# TC37XPD register map
Vendor: Infineon; Series: ATVMC; File version: 100
CPU: other r0p0, little endian, MPU, FPU, vendor SysTick, 4 interrupt priority bits
Registers are 32-bit, read-write, reset 0x0 unless marked. A register's access mark holds for its fields unless they carry their own. Offsets are from the block's base; [hi:lo] are bit positions; lines under a group give offsets from that group; {n}, {i} and the like mark numbered series; 'fields as' and 'values as' point back to an identical list.

## SRC
Base 0xF0038000
0x00 CPU group
  {0x0+4j} CPU[{j}] (j=0..2) group
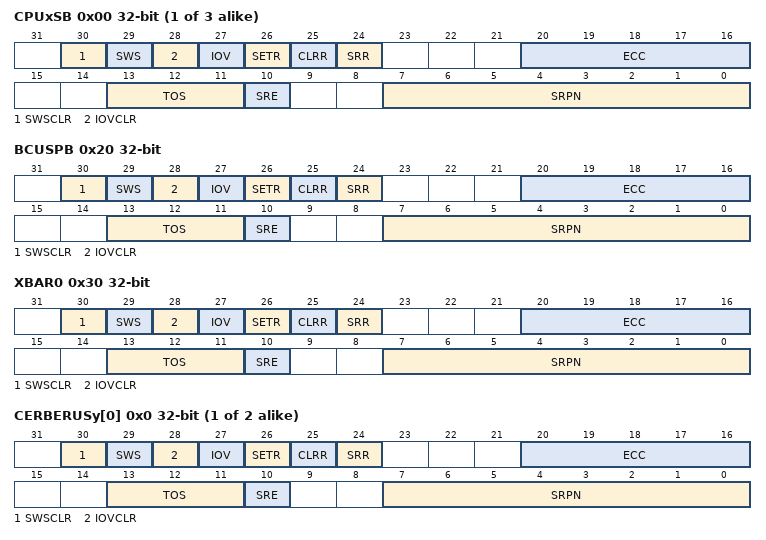
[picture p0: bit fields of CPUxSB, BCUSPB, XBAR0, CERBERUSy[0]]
    0x00 CPUxSB access per field — CPU0 Software Breakpoint Service Request resetvalue={Debug Reset:0x0}
      [30] SWSCLR wo — SW Sticky Clear Bit. SWSCLR is required to reset SWS SWS .
      [29] SWS ro — SW Sticky Bit. The Software Sticky Bit is set when the SRR SRR bit has been set via the SETR SETR bit. This bit can be cleared by writing with 1 to SWSCLR SWSCLR . Writing to SWS has no effect.
      [28] IOVCLR wo — Interrupt Trigger Overflow Clear Bit. IOVCLR is required to reset IOV IOV .
      [27] IOV ro — Interrupt Trigger Overflow Bit. The IOV bit is set by HW if a new service request was triggered via interrupt trigger or SETR SETR bit while the SRN has still an pending service request.
      [26] SETR wo — Request Set Bit. The SETR bit is required to set SRR SRR .
      [25] CLRR wo — Request Clear Bit. The CLRR bit is required to reset SRR SRR .
      [24] SRR ro — Service Request Flag. The SRR bit shows the status of the Service Request.
      [20:16] ECC rw — Error Correction Code. The ECC bit field will be updated by the SRN under the following conditions Write or Read Modify Write to SRC 31 0 Write to SRC 15 0 16 bit write Write to SRC 15 8 or write to SRC 7 0 byte write For more details pls. see CROSSREFERENCE . In the current implementation the ECC code is only used for error detection. Detected errors are reported to the SMU but not corrected.
      [13:11] TOS rw — Type of Service Control. The TOS bit field configuration maps a Service Request to an Interrupt Service Provider In products where DMA or CPUx is not implemented the related TOS encoding will not be used and treated as RESERVED. In products with less than 4 ISPs the effective size of the TOS bit field might be reduced to 1 or 2 bit.
      [10] SRE rw — Service Request Enable
      [7:0] SRPN rw — Service Request Priority Number. The SRPN bit field defines the priority of a service request with respect to service requests with to the same service provider same SRC.TOS configuration 00 gt Service request is on lowest priority ... FF gt Service request is on highest priority For a CPU 01 is the lowest priority as 00 is never serviced. For a DMA 00 triggers channel 0. For DMA SRPN must not be greater than the highest implemented DMA channel number.
0x20 BCUSPB access per field — SBCU Service Request SPB Bus Control Unit resetvalue={Debug Reset:0x0}
  fields as CPU.CPU[0].CPUxSB
0x30 XBAR0 access per field — SRI Domain 0 Service Request resetvalue={Debug Reset:0x0}
  fields as CPU.CPU[0].CPUxSB
0x40 CERBERUS group
  0x00 CERBERUS group
    {0x0+4k} CERBERUSy[{k}] (k=0..1) access per field — Cerberus Service Request 0 resetvalue={Debug Reset:0x0}
      fields as CPU.CPU[0].CPUxSB
0x50 ASCLIN group
  {0x0+0xC*j} ASCLIN[{j}] (j=0..11) group
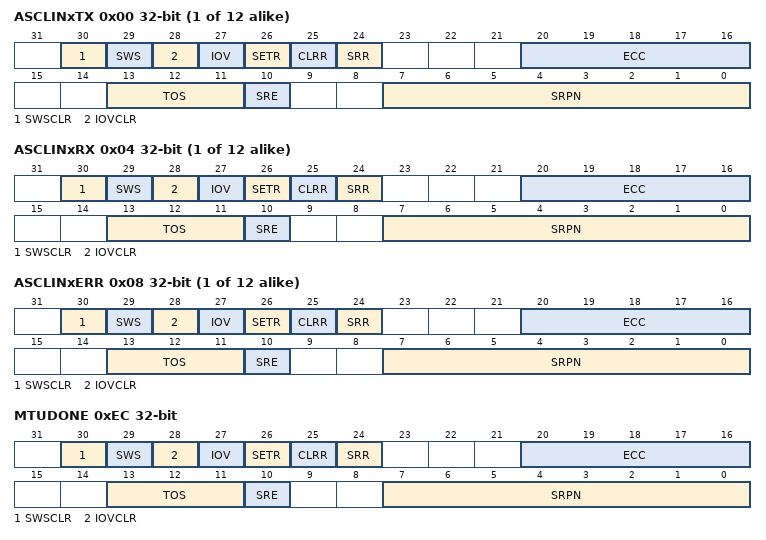
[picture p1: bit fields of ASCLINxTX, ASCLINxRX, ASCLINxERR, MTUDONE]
    0x00 ASCLINxTX access per field — ASCLIN0 Transmit Service Request resetvalue={Application Reset:0x0}
      fields as CPU.CPU[0].CPUxSB
    0x04 ASCLINxRX access per field — ASCLIN0 Receive Service Request resetvalue={Application Reset:0x0}
      fields as CPU.CPU[0].CPUxSB
    0x08 ASCLINxERR access per field — ASCLIN0 Error Service Request resetvalue={Application Reset:0x0}
      fields as CPU.CPU[0].CPUxSB
0xEC MTUDONE access per field — MTU Done Service Request resetvalue={Application Reset:0x0}
  fields as CPU.CPU[0].CPUxSB
0xF0 QSPI group
  {0x0+0x14*j} QSPI[{j}] (j=0..4) group
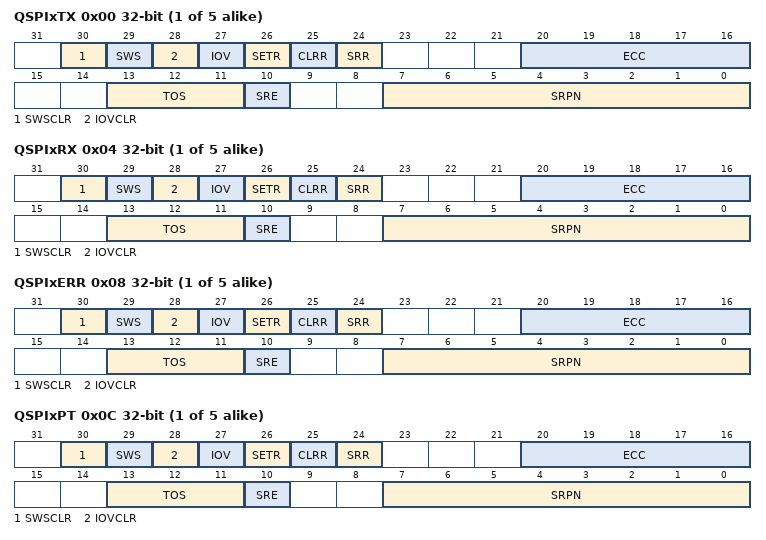
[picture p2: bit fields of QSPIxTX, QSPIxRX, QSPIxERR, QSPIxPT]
    0x00 QSPIxTX access per field — QSPI0 Transmit Service Request resetvalue={Application Reset:0x0}
      fields as CPU.CPU[0].CPUxSB
    0x04 QSPIxRX access per field — QSPI0 Receive Service Request resetvalue={Application Reset:0x0}
      fields as CPU.CPU[0].CPUxSB
    0x08 QSPIxERR access per field — QSPI0 Error Service Request resetvalue={Application Reset:0x0}
      fields as CPU.CPU[0].CPUxSB
    0x0C QSPIxPT access per field — QSPI0 Phase Transition Service Request resetvalue={Application Reset:0x0}
      fields as CPU.CPU[0].CPUxSB
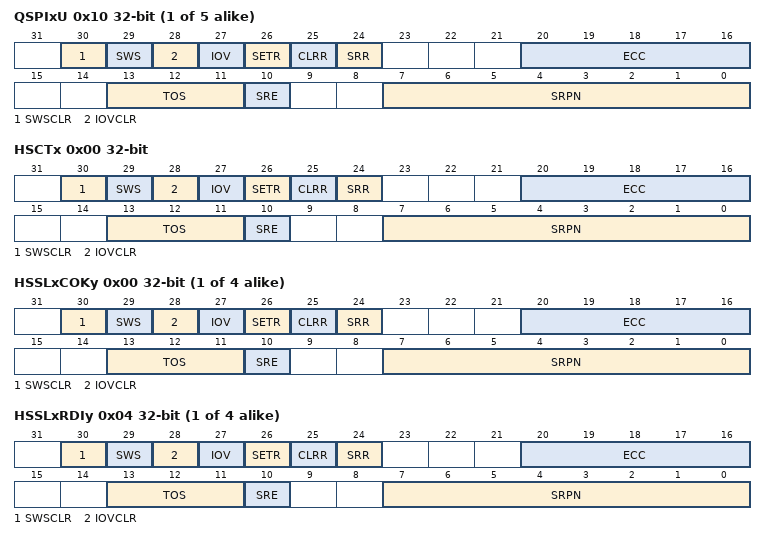
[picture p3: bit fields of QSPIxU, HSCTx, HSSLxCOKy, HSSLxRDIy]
    0x10 QSPIxU access per field — QSPI0 User Defined Service Request resetvalue={Application Reset:0x0}
      fields as CPU.CPU[0].CPUxSB
0x180 HSCT group
  {0x0+4j} HSCT[{j}] (j=0..0) group
    0x00 HSCTx access per field — HSCT0 Service Request resetvalue={Application Reset:0x0}
      fields as CPU.CPU[0].CPUxSB
0x190 HSSL group
  {0x0+0x44*j} HSSL[{j}] (j=0..0) group
    {0x0+0x10*k} CH[{k}] (k=0..3) group
      0x00 HSSLxCOKy access per field — HSSL0 Channel 0 OK Service Request resetvalue={Application Reset:0x0}
        fields as CPU.CPU[0].CPUxSB
      0x04 HSSLxRDIy access per field — HSSL0 Channel 0 Read Data Service Request resetvalue={Application Reset:0x0}
        fields as CPU.CPU[0].CPUxSB
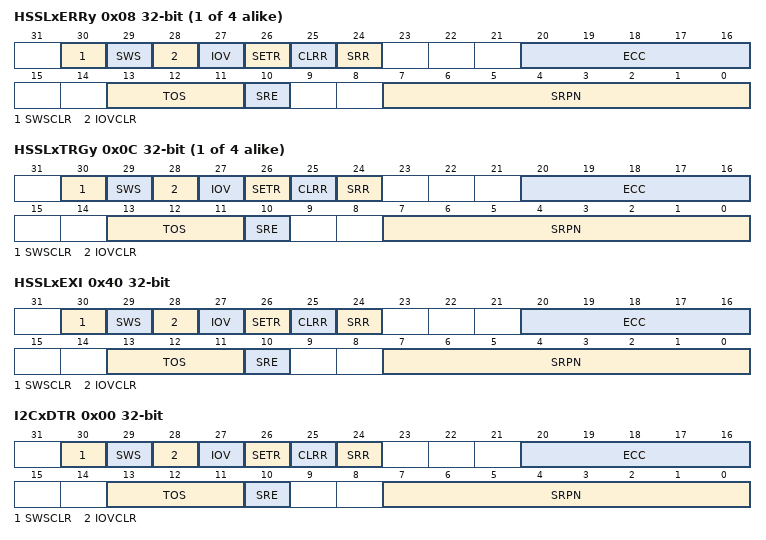
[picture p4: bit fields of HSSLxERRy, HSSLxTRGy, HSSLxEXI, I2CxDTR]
      0x08 HSSLxERRy access per field — HSSL0 Channel 0 Error Service Request resetvalue={Application Reset:0x0}
        fields as CPU.CPU[0].CPUxSB
      0x0C HSSLxTRGy access per field — HSSL0 Channel 0 Trigger Interrupt Service Request resetvalue={Application Reset:0x0}
        fields as CPU.CPU[0].CPUxSB
    0x40 HSSLxEXI access per field — HSSL0 Exception Service Request resetvalue={Application Reset:0x0}
      fields as CPU.CPU[0].CPUxSB
0x220 I2C group
  {0x0+0x10*j} I2C[{j}] (j=0..0) group
    0x00 I2CxDTR access per field — I2C0 Data Transfer Request resetvalue={Application Reset:0x0}
      fields as CPU.CPU[0].CPUxSB
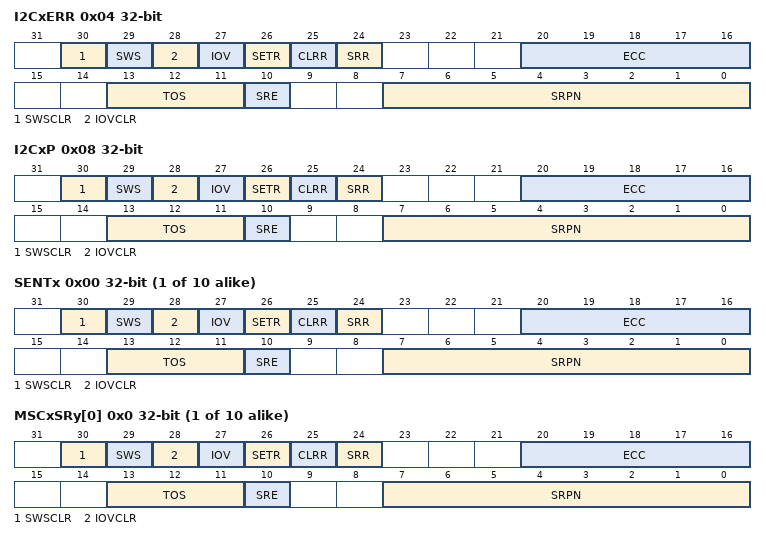
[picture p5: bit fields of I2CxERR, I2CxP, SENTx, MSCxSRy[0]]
    0x04 I2CxERR access per field — I2C0 Error Service Request resetvalue={Application Reset:0x0}
      fields as CPU.CPU[0].CPUxSB
    0x08 I2CxP access per field — I2C0 Protocol Service Request resetvalue={Application Reset:0x0}
      fields as CPU.CPU[0].CPUxSB
0x240 SENT group
  {0x0+4j} SENT[{j}] (j=0..9) group
    0x00 SENTx access per field — SENT TRIG0 Service Request resetvalue={Application Reset:0x0}
      fields as CPU.CPU[0].CPUxSB
0x270 MSC group
  {0x0+4j} MSC[{j}] (j=0..1) group
    {0x0+4k} MSCxSRy[{k}] (k=0..4) access per field — MSC0 Service Request 0 resetvalue={Application Reset:0x0}
      fields as CPU.CPU[0].CPUxSB
0x2C0 CCU6 group
  {0x0+4j} CCU[{j}] (j=0..1) group
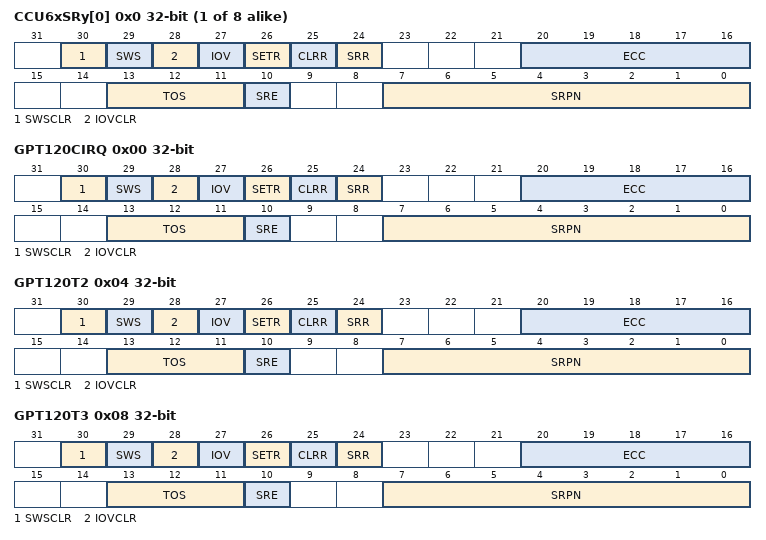
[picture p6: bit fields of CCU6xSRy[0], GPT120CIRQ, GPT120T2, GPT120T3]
    {0x0+4k} CCU6xSRy[{k}] (k=0..3) access per field — CCU0 Service Request 0 resetvalue={Application Reset:0x0}
      fields as CPU.CPU[0].CPUxSB
0x2E0 GPT12 group
  {0x0+0x18*j} GPT12[{j}] (j=0..0) group
    0x00 GPT120CIRQ access per field — GPT120 CAPREL Service Request resetvalue={Application Reset:0x0}
      fields as CPU.CPU[0].CPUxSB
    0x04 GPT120T2 access per field — GPT120 Timer 2 Service Request resetvalue={Application Reset:0x0}
      fields as CPU.CPU[0].CPUxSB
    0x08 GPT120T3 access per field — GPT120 Timer 3 Service Request resetvalue={Application Reset:0x0}
      fields as CPU.CPU[0].CPUxSB
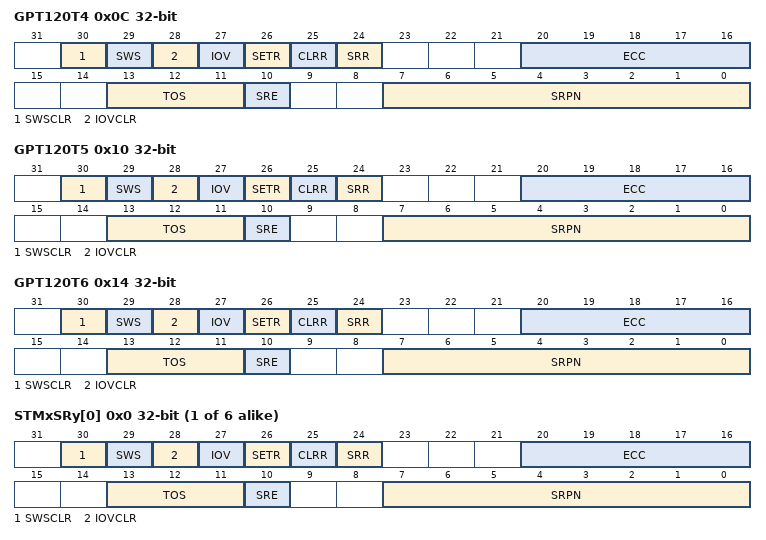
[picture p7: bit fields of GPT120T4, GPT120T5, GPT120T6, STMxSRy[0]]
    0x0C GPT120T4 access per field — GPT120 Timer 4 Service Request resetvalue={Application Reset:0x0}
      fields as CPU.CPU[0].CPUxSB
    0x10 GPT120T5 access per field — GPT120 Timer 5 Service Request resetvalue={Application Reset:0x0}
      fields as CPU.CPU[0].CPUxSB
    0x14 GPT120T6 access per field — GPT120 Timer 6 Service Request resetvalue={Application Reset:0x0}
      fields as CPU.CPU[0].CPUxSB
0x300 STM group
  {0x0+4j} STM[{j}] (j=0..2) group
    {0x0+4k} STMxSRy[{k}] (k=0..1) access per field — System Timer 0 Service Request 0 resetvalue={Application Reset:0x0}
      fields as CPU.CPU[0].CPUxSB
0x330 FCE group
  0x00 FCE0 group
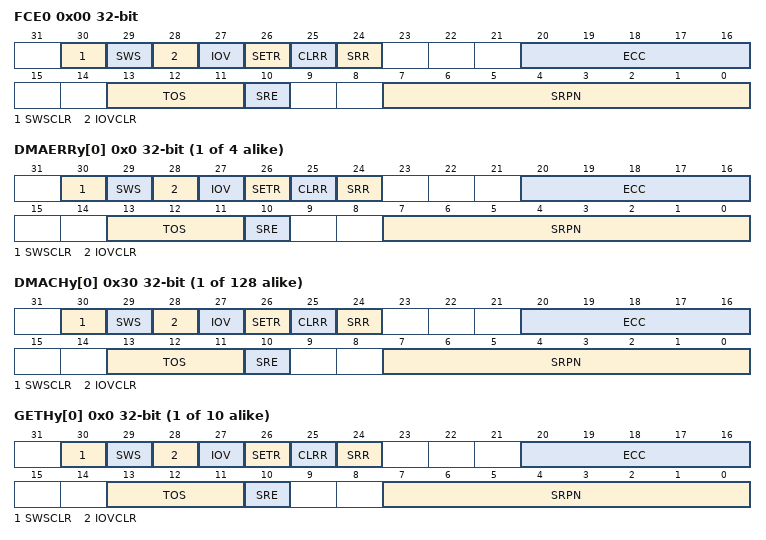
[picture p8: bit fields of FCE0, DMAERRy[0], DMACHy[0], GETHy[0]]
    0x00 FCE0 access per field — FCE0 Error Service Request resetvalue={Application Reset:0x0}
      fields as CPU.CPU[0].CPUxSB
0x340 DMA group
  {0x0+0x34*j} DMA[{j}] (j=0..0) group
    {0x0+4k} DMAERRy[{k}] (k=0..3) access per field — DMA Error Service Request 0 resetvalue={Application Reset:0x0}
      fields as CPU.CPU[0].CPUxSB
    {0x30+4k} DMACHy[{k}] (k=0..127) access per field — DMA Channel 0 Service Request resetvalue={Application Reset:0x0}
      fields as CPU.CPU[0].CPUxSB
0x580 GETH group
  {0x0+4j} GETH[{j}] (j=0..0) group
    {0x0+4k} GETHy[{k}] (k=0..9) access per field — GETH Service Request 0 resetvalue={Application Reset:0x0}
      fields as CPU.CPU[0].CPUxSB
0x5B0 CAN group
  {0x0+4j} CAN[{j}] (j=0..1) group
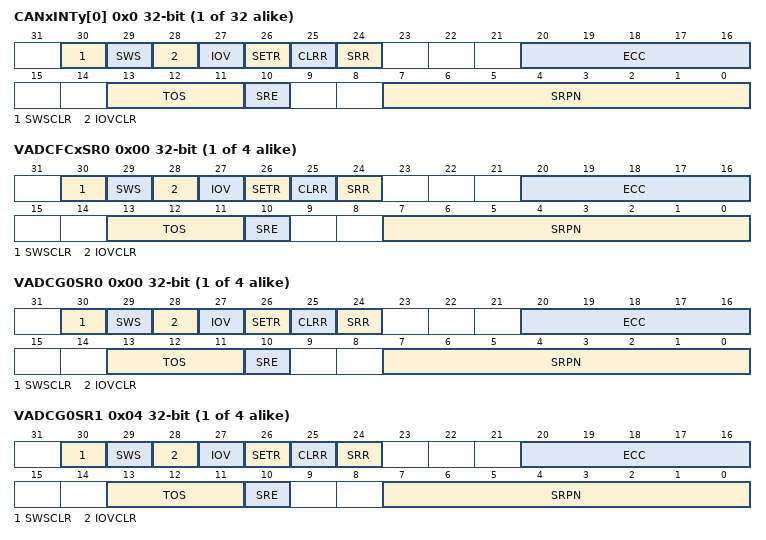
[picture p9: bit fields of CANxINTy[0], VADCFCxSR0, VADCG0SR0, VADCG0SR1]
    {0x0+4k} CANxINTy[{k}] (k=0..15) access per field — CAN0 Service Request 0 resetvalue={Application Reset:0x0}
      fields as CPU.CPU[0].CPUxSB
0x670 VADC group
  {0x0+4j} G[{j}] (j=0..3) group
    0x00 VADCG0SR0 access per field — EVADC Group 0 Service Request 3 resetvalue={Application Reset:0x0}
      fields as CPU.CPU[0].CPUxSB
    0x04 VADCG0SR1 access per field — EVADC Group 0 Service Request 3 resetvalue={Application Reset:0x0}
      fields as CPU.CPU[0].CPUxSB
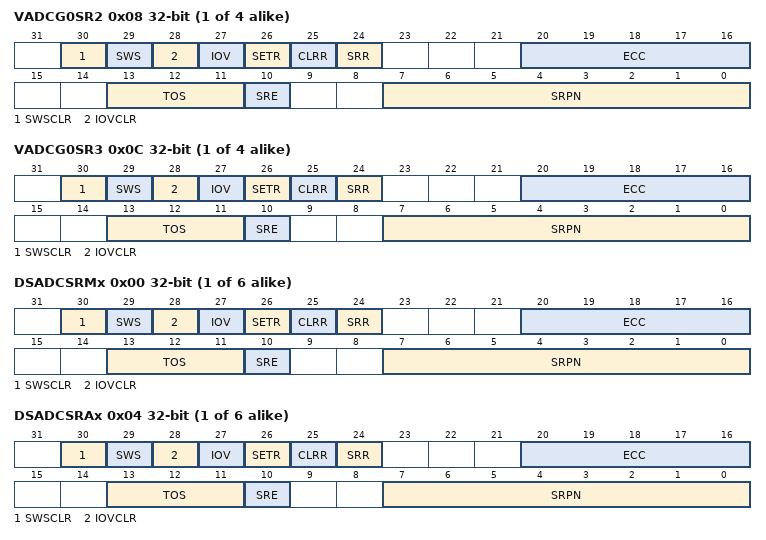
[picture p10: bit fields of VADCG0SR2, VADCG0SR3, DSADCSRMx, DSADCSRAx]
    0x08 VADCG0SR2 access per field — EVADC Group 0 Service Request 3 resetvalue={Application Reset:0x0}
      fields as CPU.CPU[0].CPUxSB
    0x0C VADCG0SR3 access per field — EVADC Group 0 Service Request 3 resetvalue={Application Reset:0x0}
      fields as CPU.CPU[0].CPUxSB
  {0x0+0x10*j} G{j} group (j=8..11)
    0x00 VADCG0SR0 access per field — EVADC Group 0 Service Request 3 resetvalue={Application Reset:0x0}
      fields as CPU.CPU[0].CPUxSB
    0x04 VADCG0SR1 access per field — EVADC Group 0 Service Request 3 resetvalue={Application Reset:0x0}
      fields as CPU.CPU[0].CPUxSB
    0x08 VADCG0SR2 access per field — EVADC Group 0 Service Request 3 resetvalue={Application Reset:0x0}
      fields as CPU.CPU[0].CPUxSB
    0x0C VADCG0SR3 access per field — EVADC Group 0 Service Request 3 resetvalue={Application Reset:0x0}
      fields as CPU.CPU[0].CPUxSB
  {0xC0+4j} FC[{j}] (j=0..3) group
    0x00 VADCFCxSR0 access per field — EVADC Fast Compare 0 Service Request SR0 resetvalue={Application Reset:0x0}
      fields as CPU.CPU[0].CPUxSB
  {0xE0+4j} CG[{j}] (j=0..1) group
    0x00 VADCG0SR0 access per field — EVADC Group 0 Service Request 3 resetvalue={Application Reset:0x0}
      fields as CPU.CPU[0].CPUxSB
    0x04 VADCG0SR1 access per field — EVADC Group 0 Service Request 3 resetvalue={Application Reset:0x0}
      fields as CPU.CPU[0].CPUxSB
    0x08 VADCG0SR2 access per field — EVADC Group 0 Service Request 3 resetvalue={Application Reset:0x0}
      fields as CPU.CPU[0].CPUxSB
    0x0C VADCG0SR3 access per field — EVADC Group 0 Service Request 3 resetvalue={Application Reset:0x0}
      fields as CPU.CPU[0].CPUxSB
0x770 DSADC group
  {0x0+8j} DSADC[{j}] (j=0..5) group
    0x00 DSADCSRMx access per field — DSADC SRM0 Service Request resetvalue={Application Reset:0x0}
      fields as CPU.CPU[0].CPUxSB
    0x04 DSADCSRAx access per field — DSADC SRA0 Service Request resetvalue={Application Reset:0x0}
      fields as CPU.CPU[0].CPUxSB
0x800 ERAY group
  {0x0+0x2C*j} ERAY[{j}] (j=0..0) group
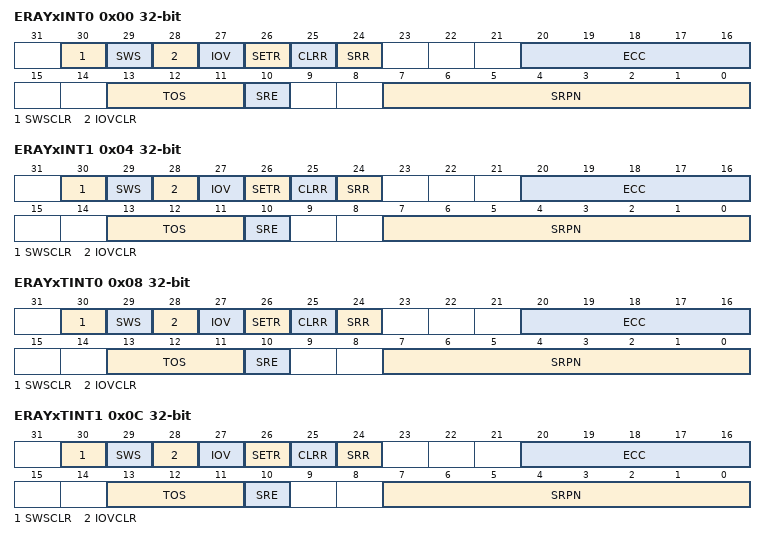
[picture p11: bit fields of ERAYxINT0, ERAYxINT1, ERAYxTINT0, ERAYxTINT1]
    0x00 ERAYxINT0 access per field — E RAY 0 Service Request 0 resetvalue={Application Reset:0x0}
      fields as CPU.CPU[0].CPUxSB
    0x04 ERAYxINT1 access per field — E RAY 0 Service Request 1 resetvalue={Application Reset:0x0}
      fields as CPU.CPU[0].CPUxSB
    0x08 ERAYxTINT0 access per field — E RAY 0 Timer Interrupt 0 Service Request resetvalue={Application Reset:0x0}
      fields as CPU.CPU[0].CPUxSB
    0x0C ERAYxTINT1 access per field — E RAY 0 Timer Interrupt 1 Service Request resetvalue={Application Reset:0x0}
      fields as CPU.CPU[0].CPUxSB
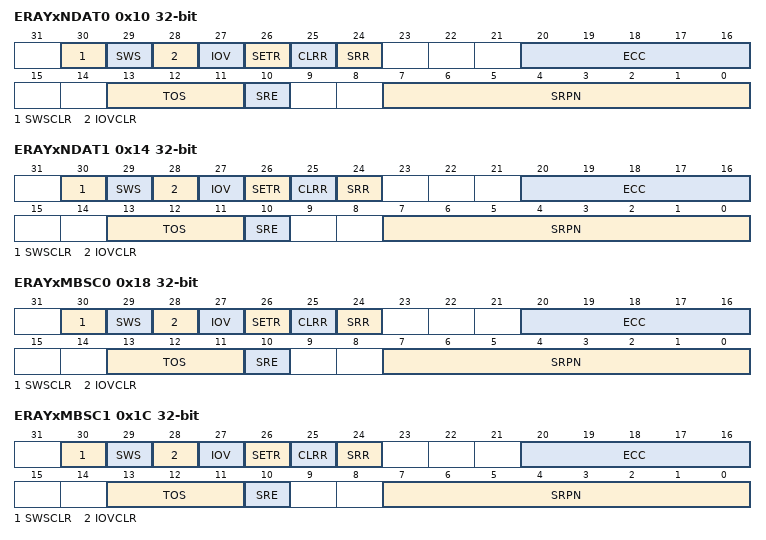
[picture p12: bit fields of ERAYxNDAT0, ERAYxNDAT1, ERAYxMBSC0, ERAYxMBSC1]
    0x10 ERAYxNDAT0 access per field — E RAY 0 New Data 0 Service Request resetvalue={Application Reset:0x0}
      fields as CPU.CPU[0].CPUxSB
    0x14 ERAYxNDAT1 access per field — E RAY 0 New Data 1 Service Request resetvalue={Application Reset:0x0}
      fields as CPU.CPU[0].CPUxSB
    0x18 ERAYxMBSC0 access per field — E RAY 0 Message Buffer Status Changed 0 Service Request resetvalue={Application Reset:0x0}
      fields as CPU.CPU[0].CPUxSB
    0x1C ERAYxMBSC1 access per field — E RAY 0 Message Buffer Status Changed 1 Service Request resetvalue={Application Reset:0x0}
      fields as CPU.CPU[0].CPUxSB
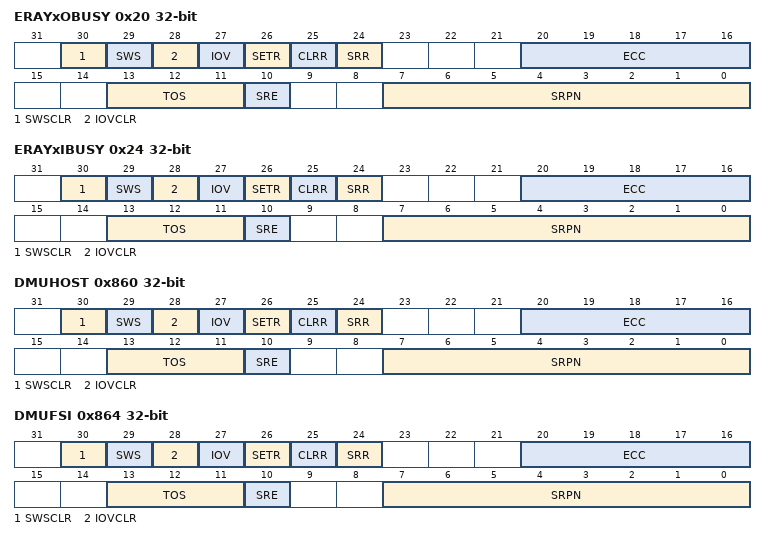
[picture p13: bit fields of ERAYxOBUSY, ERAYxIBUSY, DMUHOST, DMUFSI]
    0x20 ERAYxOBUSY access per field — E RAY 0 Output Buffer Busy resetvalue={Application Reset:0x0}
      fields as CPU.CPU[0].CPUxSB
    0x24 ERAYxIBUSY access per field — E RAY 0 Input Buffer Busy resetvalue={Application Reset:0x0}
      fields as CPU.CPU[0].CPUxSB
0x860 DMUHOST access per field — DMU Host Service Request resetvalue={Application Reset:0x0}
  fields as CPU.CPU[0].CPUxSB
0x864 DMUFSI access per field — DMU FSI Service Request resetvalue={Application Reset:0x0}
  fields as CPU.CPU[0].CPUxSB
0x870 HSM group
  {0x0+4j} HSM[{j}] (j=0..0) group
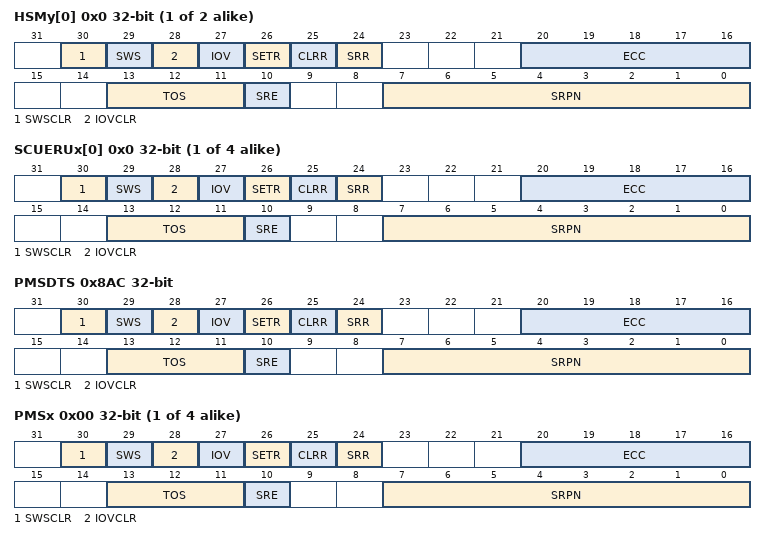
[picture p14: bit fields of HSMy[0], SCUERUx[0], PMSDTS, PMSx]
    {0x0+4k} HSMy[{k}] (k=0..1) access per field — HSM Service Request 0 resetvalue={Application Reset:0x0}
      fields as CPU.CPU[0].CPUxSB
0x880 SCU group
  {0x0+4j} SCUERUx[{j}] (j=0..3) access per field — SCU ERU Service Request 0 resetvalue={Application Reset:0x0}
    fields as CPU.CPU[0].CPUxSB
0x8AC PMSDTS access per field — PMS DTS Service Request resetvalue={Application Reset:0x0}
  fields as CPU.CPU[0].CPUxSB
0x8B0 PMS group
  {0x0+4j} PMS[{j}] (j=0..3) group
    0x00 PMSx access per field — Power Management System Service Request 0 resetvalue={Application Reset:0x0}
      fields as CPU.CPU[0].CPUxSB
0x8C0 SCR access per field — Stand By Controller Service Request resetvalue={Application Reset:0x0}
  fields as CPU.CPU[0].CPUxSB
0x8D0 SMU group
  {0x0+4j} SMU[{j}] (j=0..0) group
    {0x0+4k} SMUy[{k}] (k=0..2) access per field — SMU Service Request 0 resetvalue={Application Reset:0x0}
      fields as CPU.CPU[0].CPUxSB
0x8E0 PSI5 group
  {0x0+4j} PSI5[{j}] (j=0..0) group
    {0x0+4k} PSI5y[{k}] (k=0..7) access per field — PSI5 Service Request 0 resetvalue={Application Reset:0x0}
      fields as CPU.CPU[0].CPUxSB
0x910 DAM group
  {0x0+0x18*j} dAM[{j}] (j=0..0) group
    0x00 DAMxLI0 access per field — DAM0 Limit 0 Service Request resetvalue={Application Reset:0x0}
      fields as CPU.CPU[0].CPUxSB
    0x04 DAMxRI0 access per field — DAM0 Ready 0 Service Reques resetvalue={Application Reset:0x0}
      fields as CPU.CPU[0].CPUxSB
    0x08 DAMxLI1 access per field — DAM0 Limit 1 Service Request resetvalue={Application Reset:0x0}
      fields as CPU.CPU[0].CPUxSB
    0x0C DAMxRI1 access per field — DAM0 Ready 1 Service Request resetvalue={Application Reset:0x0}
      fields as CPU.CPU[0].CPUxSB
    0x10 DAMxDR access per field — DAM0 DMA Ready Service Request resetvalue={Application Reset:0x0}
      fields as CPU.CPU[0].CPUxSB
    0x14 DAMxERR access per field — DAM0 Error Service Request resetvalue={Application Reset:0x0}
      fields as CPU.CPU[0].CPUxSB
0x950 PSI5S group
  {0x0+4j} PSI5S[{j}] (j=0..0) group
    {0x0+4k} PSI5Sy[{k}] (k=0..7) access per field — PSI5 S Service Request 0 resetvalue={Application Reset:0x0}
      fields as CPU.CPU[0].CPUxSB
0x990 GPSR group
  {0x0+4j} GPSR[{j}] (j=0..2) group
    {0x0+4k} GPSRxy[{k}] (k=0..7) access per field — General Purpose Group 0 Service Request 0 resetvalue={Application Reset:0x0}
      fields as CPU.CPU[0].CPUxSB
0xA70 GTMAEIIRQ access per field — AEI Shared Service Request resetvalue={Application Reset:0x0}
  fields as CPU.CPU[0].CPUxSB
{0xA74+4i} GTMARUIRQw[{i}] (i=0..2) access per field — ARU Shared Service Request 0 resetvalue={Application Reset:0x0}
  fields as CPU.CPU[0].CPUxSB
0xA80 GTMBRCIRQ access per field — BRC Shared Service Request resetvalue={Application Reset:0x0}
  fields as CPU.CPU[0].CPUxSB
0xA84 GTMCMPIRQ access per field — CMP Shared Service Request resetvalue={Application Reset:0x0}
  fields as CPU.CPU[0].CPUxSB
{0xA88+4i} GTMSPEwIRQ[{i}] (i=0..1) access per field — SPE0 Shared Service Request resetvalue={Application Reset:0x0}
  fields as CPU.CPU[0].CPUxSB
{0xAA0+4i} GTMPSMwx[{i}] (i=0..7) access per field — PSM0 Shared Service Request 0 resetvalue={Application Reset:0x0}
  fields as CPU.CPU[0].CPUxSB
{0xB00+4i} GTMDPLLw[{i}] (i=0..26) access per field — DPLL Service Request 0 resetvalue={Application Reset:0x0}
  fields as CPU.CPU[0].CPUxSB
0xB70 GTMERR access per field — Error Service Request resetvalue={Application Reset:0x0}
  fields as CPU.CPU[0].CPUxSB
{0xB90+4i} GTMTIMwx[{i}] (i=0..5) group — TIM
  {0x0+4j} GTMTIMwx_[{j}] (j=0..7) access per field — TIM0 Shared Service Request 0 resetvalue={Application Reset:0x0}
    fields as CPU.CPU[0].CPUxSB
{0xCB0+4i} GTMMCSwx[{i}] (i=0..4) group — MCS
  {0x0+4j} GTMMCSwx_[{j}] (j=0..7) access per field — MCS0 Shared Service Request 0 resetvalue={Application Reset:0x0}
    fields as CPU.CPU[0].CPUxSB
{0xE10+4i} GTMTOMwx[{i}] (i=0..2) group — TOM
  {0x0+4j} GTMTOMwx_[{j}] (j=0..7) access per field — TOM0 Shared Service Request 0 resetvalue={Application Reset:0x0}
    fields as CPU.CPU[0].CPUxSB
{0xEF0+4i} GTMATOMwx[{i}] (i=0..5) group — ATOM
  {0x0+4j} GTMATOMwx_[{j}] (j=0..3) access per field — ATOM0 Shared Service Request 0 resetvalue={Application Reset:0x0}
    fields as CPU.CPU[0].CPUxSB
{0xFD0+4i} GTMMCSWw[{i}] (i=0..9) access per field — GTM Multi Channel Sequencer Service Request 0 resetvalue={Application Reset:0x0}
  fields as CPU.CPU[0].CPUxSB
